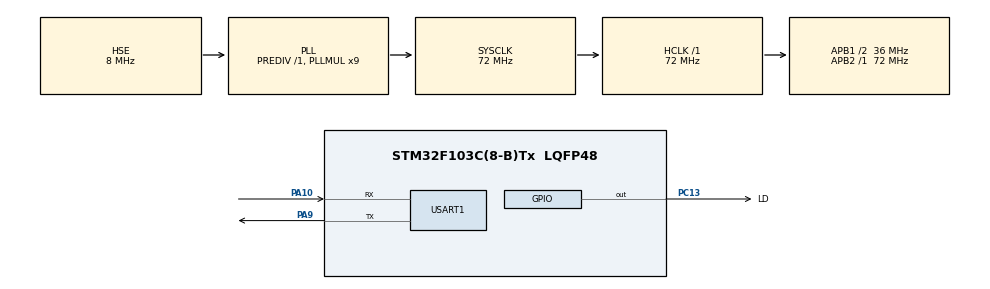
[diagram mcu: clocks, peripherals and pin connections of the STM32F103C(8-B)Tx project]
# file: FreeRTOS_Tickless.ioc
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FREERTOS.Tasks01=defaultTask,0,128,StartDefaultTask,Default,NULL,Dynamic,NULL,NULL;SysInfoTask,-2,128,StartSysInfoTask,Default,NULL,Dynamic,NULL,NULL
FREERTOS.configENABLE_BACKWARD_COMPATIBILITY=0
FREERTOS.configGENERATE_RUN_TIME_STATS=1
FREERTOS.configIDLE_SHOULD_YIELD=0
FREERTOS.configTOTAL_HEAP_SIZE=4096
FREERTOS.configUSE_MUTEXES=0
FREERTOS.configUSE_STATS_FORMATTING_FUNCTIONS=1
FREERTOS.configUSE_TASK_NOTIFICATIONS=0
FREERTOS.configUSE_TICKLESS_IDLE=1
FREERTOS.configUSE_TRACE_FACILITY=1
Mcu.Family=STM32F1
Mcu.Name=STM32F103C(8-B)Tx
Mcu.Package=LQFP48
NVIC.PriorityGroup=NVIC_PRIORITYGROUP_4
NVIC.TIM3_IRQn=true\:0\:0\:true\:false\:true\:false\:true
NVIC.TIM4_IRQn=true\:0\:0\:false\:false\:true\:false\:false
NVIC.TimeBase=TIM4_IRQn
NVIC.TimeBaseIP=TIM4
PA10.Mode=Asynchronous
PA10.Signal=USART1_RX
PA13.Mode=Serial_Wire
PA13.Signal=SYS_JTMS-SWDIO
PA14.Mode=Serial_Wire
PA14.Signal=SYS_JTCK-SWCLK
PA9.Mode=Asynchronous
PA9.Signal=USART1_TX
PC13-TAMPER-RTC.GPIO_Label=LD
PC13-TAMPER-RTC.GPIO_Speed=GPIO_SPEED_FREQ_HIGH
PC13-TAMPER-RTC.Signal=GPIO_Output
PC14-OSC32_IN.Mode=LSE-External-Oscillator
PC14-OSC32_IN.Signal=RCC_OSC32_IN
PC15-OSC32_OUT.Mode=LSE-External-Oscillator
PC15-OSC32_OUT.Signal=RCC_OSC32_OUT
PD0-OSC_IN.Mode=HSE-External-Oscillator
PD0-OSC_IN.Signal=RCC_OSC_IN
PD1-OSC_OUT.Mode=HSE-External-Oscillator
PD1-OSC_OUT.Signal=RCC_OSC_OUT
ProjectManager.HeapSize=0x200
ProjectManager.StackSize=0x400
ProjectManager.TargetToolchain=TrueSTUDIO
RCC.AHBFreq_Value=72000000
RCC.APB1CLKDivider=RCC_HCLK_DIV2
RCC.APB1Freq_Value=36000000
RCC.APB1TimFreq_Value=72000000
RCC.APB2Freq_Value=72000000
RCC.APB2TimFreq_Value=72000000
RCC.HCLKFreq_Value=72000000
RCC.PLLMUL=RCC_PLL_MUL9
RCC.PLLSourceVirtual=RCC_PLLSOURCE_HSE
RCC.SYSCLKFreq_VALUE=72000000
RCC.SYSCLKSource=RCC_SYSCLKSOURCE_PLLCLK
RCC.USBFreq_Value=72000000
TIM3.Period=100-1
TIM3.Prescaler=72-1
USART1.VirtualMode=VM_ASYNC
VP_FREERTOS_VS_ENABLE.Mode=Enabled
VP_SYS_VS_tim4.Mode=TIM4
VP_TIM3_VS_ClockSourceINT.Mode=Internal
board=custom

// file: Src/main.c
/* USER CODE BEGIN Header */
/**
  ******************************************************************************
  * @file           : main.c
  * @brief          : Main program body
  ******************************************************************************
  * This notice applies to any and all portions of this file
  * that are not between comment pairs USER CODE BEGIN and
  * USER CODE END. Other portions of this file, whether
  * inserted by the user or by software development tools
  * are owned by their respective copyright owners.
  *
  * Copyright (c) 2018 STMicroelectronics International N.V.
  * All rights reserved.
  *
  * Redistribution and use in source and binary forms, with or without
  * modification, are permitted, provided that the following conditions are met:
  *
  * 1. Redistribution of source code must retain the above copyright notice,
  *    this list of conditions and the following disclaimer.
  * 2. Redistributions in binary form must reproduce the above copyright notice,
  *    this list of conditions and the following disclaimer in the documentation
  *    and/or other materials provided with the distribution.
  * 3. Neither the name of STMicroelectronics nor the names of other
  *    contributors to this software may be used to endorse or promote products
  *    derived from this software without specific written permission.
  * 4. This software, including modifications and/or derivative works of this
  *    software, must execute solely and exclusively on microcontroller or
  *    microprocessor devices manufactured by or for STMicroelectronics.
  * 5. Redistribution and use of this software other than as permitted under
  *    this license is void and will automatically terminate your rights under
  *    this license.
  *
  * THIS SOFTWARE IS PROVIDED BY STMICROELECTRONICS AND CONTRIBUTORS "AS IS"
  * AND ANY EXPRESS, IMPLIED OR STATUTORY WARRANTIES, INCLUDING, BUT NOT
  * LIMITED TO, THE IMPLIED WARRANTIES OF MERCHANTABILITY, FITNESS FOR A
  * PARTICULAR PURPOSE AND NON-INFRINGEMENT OF THIRD PARTY INTELLECTUAL PROPERTY
  * RIGHTS ARE DISCLAIMED TO THE FULLEST EXTENT PERMITTED BY LAW. IN NO EVENT
  * SHALL STMICROELECTRONICS OR CONTRIBUTORS BE LIABLE FOR ANY DIRECT, INDIRECT,
  * INCIDENTAL, SPECIAL, EXEMPLARY, OR CONSEQUENTIAL DAMAGES (INCLUDING, BUT NOT
  * LIMITED TO, PROCUREMENT OF SUBSTITUTE GOODS OR SERVICES; LOSS OF USE, DATA,
  * OR PROFITS; OR BUSINESS INTERRUPTION) HOWEVER CAUSED AND ON ANY THEORY OF
  * LIABILITY, WHETHER IN CONTRACT, STRICT LIABILITY, OR TORT (INCLUDING
  * NEGLIGENCE OR OTHERWISE) ARISING IN ANY WAY OUT OF THE USE OF THIS SOFTWARE,
  * EVEN IF ADVISED OF THE POSSIBILITY OF SUCH DAMAGE.
  *
  ******************************************************************************
  */
/* USER CODE END Header */

#include "main.h"
#include "cmsis_os.h"
#include "tim.h"
#include "usart.h"
#include "gpio.h"

/* USER CODE BEGIN PV */
/* Private variables ---------------------------------------------------------*/
uint32_t RunTimeCounter;
/* USER CODE END PV */

void SystemClock_Config(void);
void MX_FREERTOS_Init(void);
/* USER CODE BEGIN PFP */
/* Private function prototypes -----------------------------------------------*/

/* USER CODE END PFP */

int main(void)
{

  /* MCU Configuration--------------------------------------------------------*/

  /* Reset of all peripherals, Initializes the Flash interface and the Systick. */
  HAL_Init();

  /* Configure the system clock */
  SystemClock_Config();

  /* Initialize all configured peripherals */
  MX_GPIO_Init();
  MX_TIM3_Init();
  MX_USART1_UART_Init();
  /* USER CODE BEGIN 2 */
  HAL_TIM_Base_Start_IT(&htim3);
  /* USER CODE END 2 */

  /* Call init function for freertos objects (in freertos.c) */
  MX_FREERTOS_Init();

  /* Start scheduler */
  osKernelStart();

  /* We should never get here as control is now taken by the scheduler */

  /* Infinite loop */
  while (1)
  {

  }
}

void SystemClock_Config(void)
{
  RCC_OscInitTypeDef RCC_OscInitStruct = {0};
  RCC_ClkInitTypeDef RCC_ClkInitStruct = {0};

  /**Initializes the CPU, AHB and APB busses clocks
  */
  RCC_OscInitStruct.OscillatorType = RCC_OSCILLATORTYPE_HSE;
  RCC_OscInitStruct.HSEState = RCC_HSE_ON;
  RCC_OscInitStruct.HSEPredivValue = RCC_HSE_PREDIV_DIV1;
  RCC_OscInitStruct.HSIState = RCC_HSI_ON;
  RCC_OscInitStruct.PLL.PLLState = RCC_PLL_ON;
  RCC_OscInitStruct.PLL.PLLSource = RCC_PLLSOURCE_HSE;
  RCC_OscInitStruct.PLL.PLLMUL = RCC_PLL_MUL9;
  if (HAL_RCC_OscConfig(&RCC_OscInitStruct) != HAL_OK)
  {
    Error_Handler();
  }
  /**Initializes the CPU, AHB and APB busses clocks
  */
  RCC_ClkInitStruct.ClockType = RCC_CLOCKTYPE_HCLK|RCC_CLOCKTYPE_SYSCLK
                              |RCC_CLOCKTYPE_PCLK1|RCC_CLOCKTYPE_PCLK2;
  RCC_ClkInitStruct.SYSCLKSource = RCC_SYSCLKSOURCE_PLLCLK;
  RCC_ClkInitStruct.AHBCLKDivider = RCC_SYSCLK_DIV1;
  RCC_ClkInitStruct.APB1CLKDivider = RCC_HCLK_DIV2;
  RCC_ClkInitStruct.APB2CLKDivider = RCC_HCLK_DIV1;

  if (HAL_RCC_ClockConfig(&RCC_ClkInitStruct, FLASH_LATENCY_2) != HAL_OK)
  {
    Error_Handler();
  }
}

void HAL_TIM_PeriodElapsedCallback(TIM_HandleTypeDef *htim)
{
  if (htim->Instance == TIM4) {
    HAL_IncTick();
  }
  /* USER CODE BEGIN Callback 1 */
    if (htim->Instance == TIM3) {
    RunTimeCounter++;
  }
  /* USER CODE END Callback 1 */
}

void Error_Handler(void)
{
  while(1)
  {
  }
}

/************************ (C) COPYRIGHT STMicroelectronics *****END OF FILE****/

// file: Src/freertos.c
/* USER CODE BEGIN Header */
/**
  ******************************************************************************
  * File Name          : freertos.c
  * Description        : Code for freertos applications
  ******************************************************************************
  * This notice applies to any and all portions of this file
  * that are not between comment pairs USER CODE BEGIN and
  * USER CODE END. Other portions of this file, whether
  * inserted by the user or by software development tools
  * are owned by their respective copyright owners.
  *
  * Copyright (c) 2018 STMicroelectronics International N.V.
  * All rights reserved.
  *
  * Redistribution and use in source and binary forms, with or without
  * modification, are permitted, provided that the following conditions are met:
  *
  * 1. Redistribution of source code must retain the above copyright notice,
  *    this list of conditions and the following disclaimer.
  * 2. Redistributions in binary form must reproduce the above copyright notice,
  *    this list of conditions and the following disclaimer in the documentation
  *    and/or other materials provided with the distribution.
  * 3. Neither the name of STMicroelectronics nor the names of other
  *    contributors to this software may be used to endorse or promote products
  *    derived from this software without specific written permission.
  * 4. This software, including modifications and/or derivative works of this
  *    software, must execute solely and exclusively on microcontroller or
  *    microprocessor devices manufactured by or for STMicroelectronics.
  * 5. Redistribution and use of this software other than as permitted under
  *    this license is void and will automatically terminate your rights under
  *    this license.
  *
  * THIS SOFTWARE IS PROVIDED BY STMICROELECTRONICS AND CONTRIBUTORS "AS IS"
  * AND ANY EXPRESS, IMPLIED OR STATUTORY WARRANTIES, INCLUDING, BUT NOT
  * LIMITED TO, THE IMPLIED WARRANTIES OF MERCHANTABILITY, FITNESS FOR A
  * PARTICULAR PURPOSE AND NON-INFRINGEMENT OF THIRD PARTY INTELLECTUAL PROPERTY
  * RIGHTS ARE DISCLAIMED TO THE FULLEST EXTENT PERMITTED BY LAW. IN NO EVENT
  * SHALL STMICROELECTRONICS OR CONTRIBUTORS BE LIABLE FOR ANY DIRECT, INDIRECT,
  * INCIDENTAL, SPECIAL, EXEMPLARY, OR CONSEQUENTIAL DAMAGES (INCLUDING, BUT NOT
  * LIMITED TO, PROCUREMENT OF SUBSTITUTE GOODS OR SERVICES; LOSS OF USE, DATA,
  * OR PROFITS; OR BUSINESS INTERRUPTION) HOWEVER CAUSED AND ON ANY THEORY OF
  * LIABILITY, WHETHER IN CONTRACT, STRICT LIABILITY, OR TORT (INCLUDING
  * NEGLIGENCE OR OTHERWISE) ARISING IN ANY WAY OUT OF THE USE OF THIS SOFTWARE,
  * EVEN IF ADVISED OF THE POSSIBILITY OF SUCH DAMAGE.
  *
  ******************************************************************************
  */
/* USER CODE END Header */

#include "FreeRTOS.h"
#include "task.h"
#include "main.h"
#include "cmsis_os.h"

/* USER CODE BEGIN Includes */
#include "gpio.h"
#include "usart.h"

#include "printf_scanf.h"
/* USER CODE END Includes */

/* USER CODE BEGIN Variables */
extern uint32_t RunTimeCounter;
/* USER CODE END Variables */
osThreadId defaultTaskHandle;
osThreadId SysInfoTaskHandle;

void StartDefaultTask(void const * argument);
void StartSysInfoTask(void const * argument);

void MX_FREERTOS_Init(void); /* (MISRA C 2004 rule 8.1) */

/* Pre/Post sleep processing prototypes */
void PreSleepProcessing(uint32_t *ulExpectedIdleTime);
void PostSleepProcessing(uint32_t *ulExpectedIdleTime);

/* Hook prototypes */
void configureTimerForRunTimeStats(void);
unsigned long getRunTimeCounterValue(void);

/* USER CODE BEGIN 1 */
/* Functions needed when configGENERATE_RUN_TIME_STATS is on */
__weak void configureTimerForRunTimeStats(void)
{
 RunTimeCounter=0UL;
}

__weak unsigned long getRunTimeCounterValue(void)
{
return RunTimeCounter;
}
/* USER CODE END 1 */

/* USER CODE BEGIN PREPOSTSLEEP */
__weak void PreSleepProcessing(uint32_t *ulExpectedIdleTime)
{
/* place for user code */
//	 printf(" Enter Sleep ");
}

__weak void PostSleepProcessing(uint32_t *ulExpectedIdleTime)
{
/* place for user code */
//	 printf(" Exit Sleep ");
}
/* USER CODE END PREPOSTSLEEP */

void MX_FREERTOS_Init(void) {

  /* Create the thread(s) */
  /* definition and creation of defaultTask */
  osThreadDef(defaultTask, StartDefaultTask, osPriorityNormal, 0, 128);
  defaultTaskHandle = osThreadCreate(osThread(defaultTask), NULL);

  /* definition and creation of SysInfoTask */
  osThreadDef(SysInfoTask, StartSysInfoTask, osPriorityLow, 0, 128);
  SysInfoTaskHandle = osThreadCreate(osThread(SysInfoTask), NULL);

}

void StartDefaultTask(void const * argument)
{

  /* USER CODE BEGIN StartDefaultTask */
  /* Infinite loop */
  for(;;)
  {
    HAL_GPIO_TogglePin(LD_GPIO_Port, LD_Pin);
    osDelay(100);
  }
  /* USER CODE END StartDefaultTask */
}

void StartSysInfoTask(void const * argument)
{
  /* USER CODE BEGIN StartSysInfoTask */
		char run_Buf[64];
  /* Infinite loop */

  /* Infinite loop */
  for(;;)
  {
	   vTaskList(run_Buf);
   	printf("Task name   Status  Priority    Stack    Number \r\n");
	   printf("%s \r\n",run_Buf);
    vTaskGetRunTimeStats(run_Buf);
   	printf("Task name      Count      precentage \r\n");
	   printf("%s \r\n",run_Buf);
    osDelay(500);
  }
  /* USER CODE END StartSysInfoTask */
}

/************************ (C) COPYRIGHT STMicroelectronics *****END OF FILE****/
